# MCXN947_cm33_core0 register map
Vendor: nxp.com; File version: 1.0
CPU: CM33 r2p0, little endian, MPU, FPU, VTOR, 3 interrupt priority bits
Registers are 32-bit, read-write, reset 0x0 unless marked. A register's access mark holds for its fields unless they carry their own. Offsets are from the block's base; [hi:lo] are bit positions; {n}, {i} and the like mark numbered series.

## POWERQUAD
Base 0x400BF000
0x00 OUTBASE — Output Base
  [31:0] OUTBASE — Base address for the output region
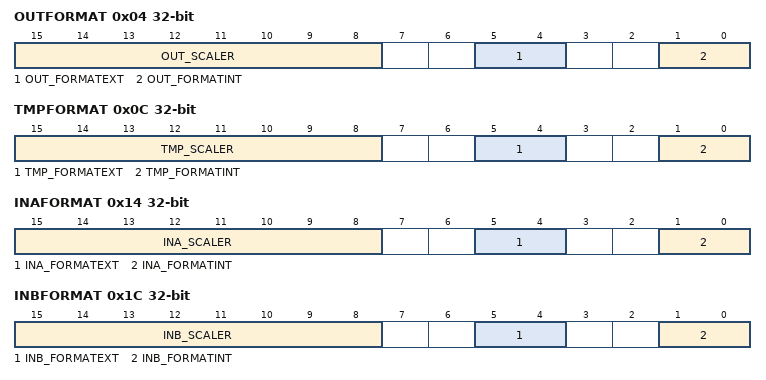
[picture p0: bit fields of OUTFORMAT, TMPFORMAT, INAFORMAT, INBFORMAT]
0x04 OUTFORMAT — Output Format
  [15:8] OUT_SCALER — Output scaler value
  [5:4] OUT_FORMATEXT — Output external format
    0=Q15; 1=Q31; 2=FLOAT
  [1:0] OUT_FORMATINT — Output internal format
    0=Q15; 1=Q31; 2=FLOAT
0x08 TMPBASE — Temporary Base
  [31:0] TMPBASE — Base address for the temporary region
0x0C TMPFORMAT — Temporary Format
  [15:8] TMP_SCALER — Temporary scaler value
  [5:4] TMP_FORMATEXT — Temporary external format
    0=Q15; 1=Q31; 2=FLOAT
  [1:0] TMP_FORMATINT — Temporary internal format
    0=Q15; 1=Q31; 2=FLOAT
0x10 INABASE — Input A base
0x14 INAFORMAT — Input A format
  [15:8] INA_SCALER — Input A scaler value
  [5:4] INA_FORMATEXT — Input A external format
    0=Q15; 1=Q31; 2=FLOAT
  [1:0] INA_FORMATINT — Input A internal format
    0=Q15; 1=Q31; 2=FLOAT
0x18 INBBASE — Input B base
0x1C INBFORMAT — Input B format
  [15:8] INB_SCALER — Input B scaler value
  [5:4] INB_FORMATEXT — Input B external format
    0=Q15; 1=Q31; 2=FLOAT
  [1:0] INB_FORMATINT — Input B internal format
    0=Q15; 1=Q31; 2=FLOAT
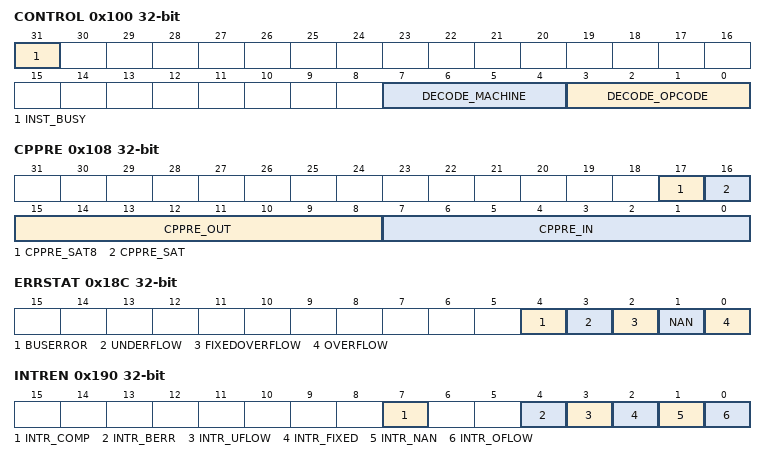
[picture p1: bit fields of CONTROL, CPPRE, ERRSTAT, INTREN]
0x100 CONTROL
  [31] INST_BUSY ro — Instruction busy
    0=NOT_BUSY; 1=BUSY
  [7:4] DECODE_MACHINE
  [3:0] DECODE_OPCODE
0x104 LENGTH
  [31:0] INST_LENGTH — Instruction length
0x108 CPPRE — Coprocessor Pre-scale
  [17] CPPRE_SAT8 — Saturation 8
    0=SAT_8_BITS (8 bits); 1=SAT_16_BITS (16 bits)
  [16] CPPRE_SAT — Saturation
    0=DISABLE (No saturation); 1=ENABLE (Forces sub-32 bit saturation)
  [15:8] CPPRE_OUT — Output
  [7:0] CPPRE_IN — Input
0x10C MISC — Miscellaneous
  [31:0] INST_MISC — For matrix operations used for scaling factor
0x110 CURSORY
  [0] CURSORY — Cursory Mode
    0=DISABLE (Disable cursory mode); 1=ENABLE (Enable cursory Mode)
0x180 CORDIC_X — CORDIC input X
  [31:0] CORDIC_X — CORDIC input x
0x184 CORDIC_Y — CORDIC input Y
  [31:0] CORDIC_Y — CORDIC input y
0x188 CORDIC_Z — CORDIC input Z
  [31:0] CORDIC_Z — CORDIC input z
0x18C ERRSTAT write-1-clears — Error Status
  [4] BUSERROR write-1-clears
    0=NO_ERROR; 1=ERROR (Error on bus)
  [3] UNDERFLOW write-1-clears
    0=NO_ERROR; 1=ERROR (Error on underflow)
  [2] FIXEDOVERFLOW write-1-clears — Fixed point overflow
    0=NO_ERROR; 1=ERROR (Error on fixed point overflow)
  [1] NAN write-1-clears — Floating Point NaN
    0=NO_ERROR; 1=ERROR (Error on Floating Point NaN)
  [0] OVERFLOW write-1-clears — Floating point overflow
    0=NO_ERROR; 1=ERROR (Error on floating point overflow)
0x190 INTREN — Interrupt Enable
  [all] fields
    0=DISABLE (Disable interrupt); 1=ENABLE (Enable interrupt)
  [7] INTR_COMP — Interrupt on instruction completion
  [4] INTR_BERR — Interrupt on AHBM bus error
  [3] INTR_UFLOW — Interrupt on subnormal truncation
  [2] INTR_FIXED — Interrupt on fixed-point overflow
  [1] INTR_NAN — Interrupt floating point NaN
  [0] INTR_OFLOW — Interrupt floating point overflow
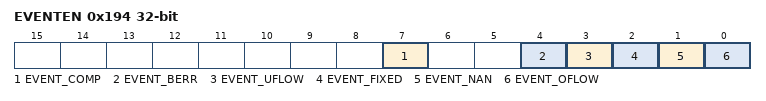
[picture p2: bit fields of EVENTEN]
0x194 EVENTEN — Event Enable
  [all] fields
    0=DISABLE (Disable event trigger); 1=ENABLE (Enable event trigger)
  [7] EVENT_COMP — Event trigger on instruction completion
  [4] EVENT_BERR — Event trigger on AHBM bus error
  [3] EVENT_UFLOW — Event trigger on subnormal truncation
  [2] EVENT_FIXED — Event trigger on fixed-point overflow
  [1] EVENT_NAN — Event trigger on floating point NaN
  [0] EVENT_OFLOW — Event trigger on floating point overflow
0x198 INTRSTAT write-1-clears — Interrupt Status
  [0] INTR_STAT write-1-clears
    0=DISABLE (No new interrupt); 1=ENABLE (Interrupt captured)
{0x200+4i} GPREG[{i}] (i=0..15) — General Purpose Register Bank n
  [31:0] GPREG — General Purpose Bank
{0x240+4i} COMPREG[{i}] (i=0..7) — Compute Register Bank n
  [31:0] COMPREG — Compute bank
